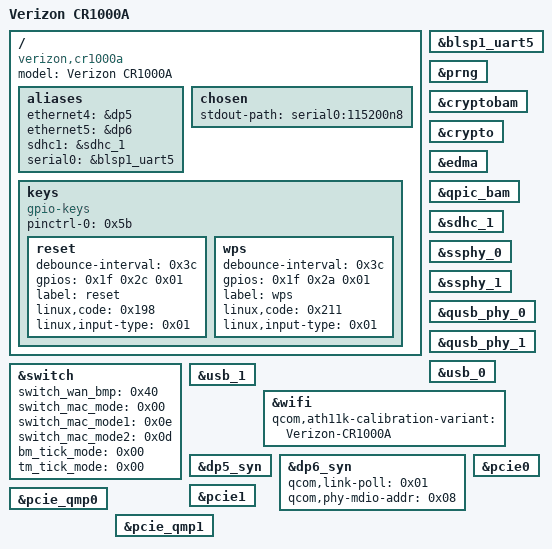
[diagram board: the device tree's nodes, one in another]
/dts-v1/;

#include "ipq8074.dtsi"
#include "ipq8074-hk-cpu.dtsi"
#include "ipq8074-ess.dtsi"

#include <dt-bindings/input/input.h>
#include <dt-bindings/gpio/gpio.h>

/ {
	model = "Verizon CR1000A";
	compatible = "verizon,cr1000a", "qcom,ipq8074";

	aliases {
		ethernet4 = &dp5;
		ethernet5 = &dp6;
		sdhc1 = &sdhc_1;
		serial0 = &blsp1_uart5;
	};
	
	chosen {
		stdout-path = "serial0:115200n8";
	};

	keys {
		compatible = "gpio-keys";
		pinctrl-0 = <0x5b>;
		pinctrl-names = "default";

		reset {
			debounce-interval = <0x3c>;
			gpios = <0x1f 0x2c 0x01>;
			label = "reset";
			linux,code = <0x198>;
			linux,input-type = <0x01>;
		};

		wps {
			debounce-interval = <0x3c>;
			gpios = <0x1f 0x2a 0x01>;
			label = "wps";
			linux,code = <0x211>;
			linux,input-type = <0x01>;
		};
	};
};

&blsp1_uart5 {
	status = "okay";
};

&prng {
	status = "okay";
};

&cryptobam {
	status = "okay";
};

&crypto {
	status = "okay";
};

&edma {
	status = "okay";
};

&qpic_bam {
	status = "okay";
};

&sdhc_1 {
	status = "okay";
};

//&mdio {
//	status = "okay";

	// ethernet-phy@0 {
	// 	reg = <0x00>;
	// };

	// ethernet-phy@1 {
	// 	reg = <0x01>;
	// };

	// ethernet-phy@2 {
	// 	reg = <0x02>;
	// };

	// ethernet-phy@3 {
	// 	reg = <0x03>;
	// };

	// ethernet-phy@4 {
	// 	reg = <0x04>;
	// };

//	ethernet-phy@5 {
//		compatible = "ethernet-phy-ieee802.3-c45";
//		reg = <0x08>;
//	};
//};

&switch {
	status = "okay";

	pinctrl-names = "default";
	//switch_lan_bmp = <0x3e>; // crashes kernel 
	switch_wan_bmp = <0x40>;
	switch_mac_mode = <0x00>;
	switch_mac_mode1 = <0x0e>;
	switch_mac_mode2 = <0x0d>;
	bm_tick_mode = <0x00>;
	tm_tick_mode = <0x00>;

};

&ssphy_0 {
	status = "okay";
};

&ssphy_1 {
	status = "okay";
};

&qusb_phy_0 {
	status = "okay";
};

&qusb_phy_1 {
	status = "okay";
};

&usb_0 {
	status = "okay";

	// vbus-supply = <&reg_usb_vbus>;
};

&usb_1 {
	status = "okay";

	// vbus-supply = <&reg_usb_vbus>;
};

&wifi {
	status = "okay";
	qcom,ath11k-calibration-variant = "Verizon-CR1000A";
};

&dp5_syn {
	status = "okay";
};

&dp6_syn {
	status = "okay";
	qcom,link-poll = <0x01>;
	qcom,phy-mdio-addr = <0x08>;
};

&pcie0 {
	status = "okay";
};

&pcie_qmp0 {
	status = "okay";
};

&pcie1 {
	status = "okay";
};

&pcie_qmp1 {
	status = "okay";
};
